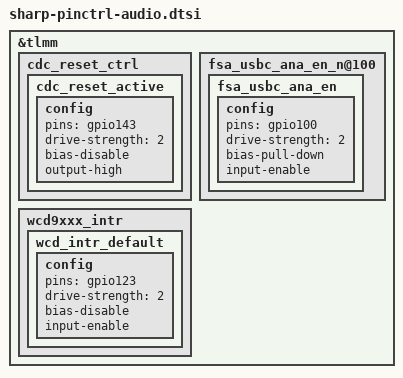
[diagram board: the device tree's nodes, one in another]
/* Copyright (c) 2016, The Linux Foundation. All rights reserved.
 *
 * This program is free software; you can redistribute it and/or modify
 * it under the terms of the GNU General Public License version 2 and
 * only version 2 as published by the Free Software Foundation.
 *
 * This program is distributed in the hope that it will be useful,
 * but WITHOUT ANY WARRANTY; without even the implied warranty of
 * MERCHANTABILITY or FITNESS FOR A PARTICULAR PURPOSE.  See the
 * GNU General Public License for more details.
 */
&tlmm{
/* SH_AUDIO_DRIVER -> */ /*A-001*/
	cdc_reset_ctrl {
		cdc_reset_active:cdc_reset_active {
			config {
				pins = "gpio143";
				drive-strength = <2>;
				bias-disable;
				output-high;
			};
		};
	};
/* SH_AUDIO_DRIVER <- */ /*A-001*/
/* SH_AUDIO_DRIVER -> */ /*A-010*/
	fsa_usbc_ana_en_n@100 {
		fsa_usbc_ana_en: fsa_usbc_ana_en {
			config {
				pins = "gpio100";
				drive-strength = <2>;
				bias-pull-down;
				input-enable;
			};
		};
	};
/* SH_AUDIO_DRIVER <- */ /*A-010*/

/* SH_AUDIO_DRIVER -> */ /*A-011*/
	wcd9xxx_intr {
		wcd_intr_default: wcd_intr_default {
			config {
				pins = "gpio123";
				drive-strength = <2>; /* 2 mA */
				bias-disable; /* NO PULL */
				input-enable;
			};
		};
	};
/* SH_AUDIO_DRIVER <- */ /*A-011*/
};
